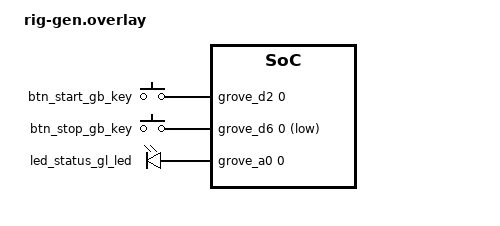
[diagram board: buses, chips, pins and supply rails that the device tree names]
/* generated by rigexp — do not edit; the rig file is the source of truth (R3)
 * rig: lotus-buttons  board: seeeduino_lotus/samd21g18a/rig
 */

/ {
	gpio_keys: gpio_keys {
		compatible = "gpio-keys";
		btn_start_gb_key: btn_start_gb_key {
			label = "btn_start_gb_key";
			zephyr,code = <11>;
			gpios = <&grove_d2 0 0x20>;	/* SIG0 */
		};
		btn_stop_gb_key: btn_stop_gb_key {
			label = "btn_stop_gb_key";
			zephyr,code = <11>;
			gpios = <&grove_d6 0 0x21>;	/* SIG0 inverted */
		};
	};
	gpio_leds: gpio_leds {
		compatible = "gpio-leds";
		led_status_gl_led: led_status_gl_led {
			label = "led_status_gl_led";
			gpios = <&grove_a0 0 0x0>;	/* SIG0 */
		};
	};
};
